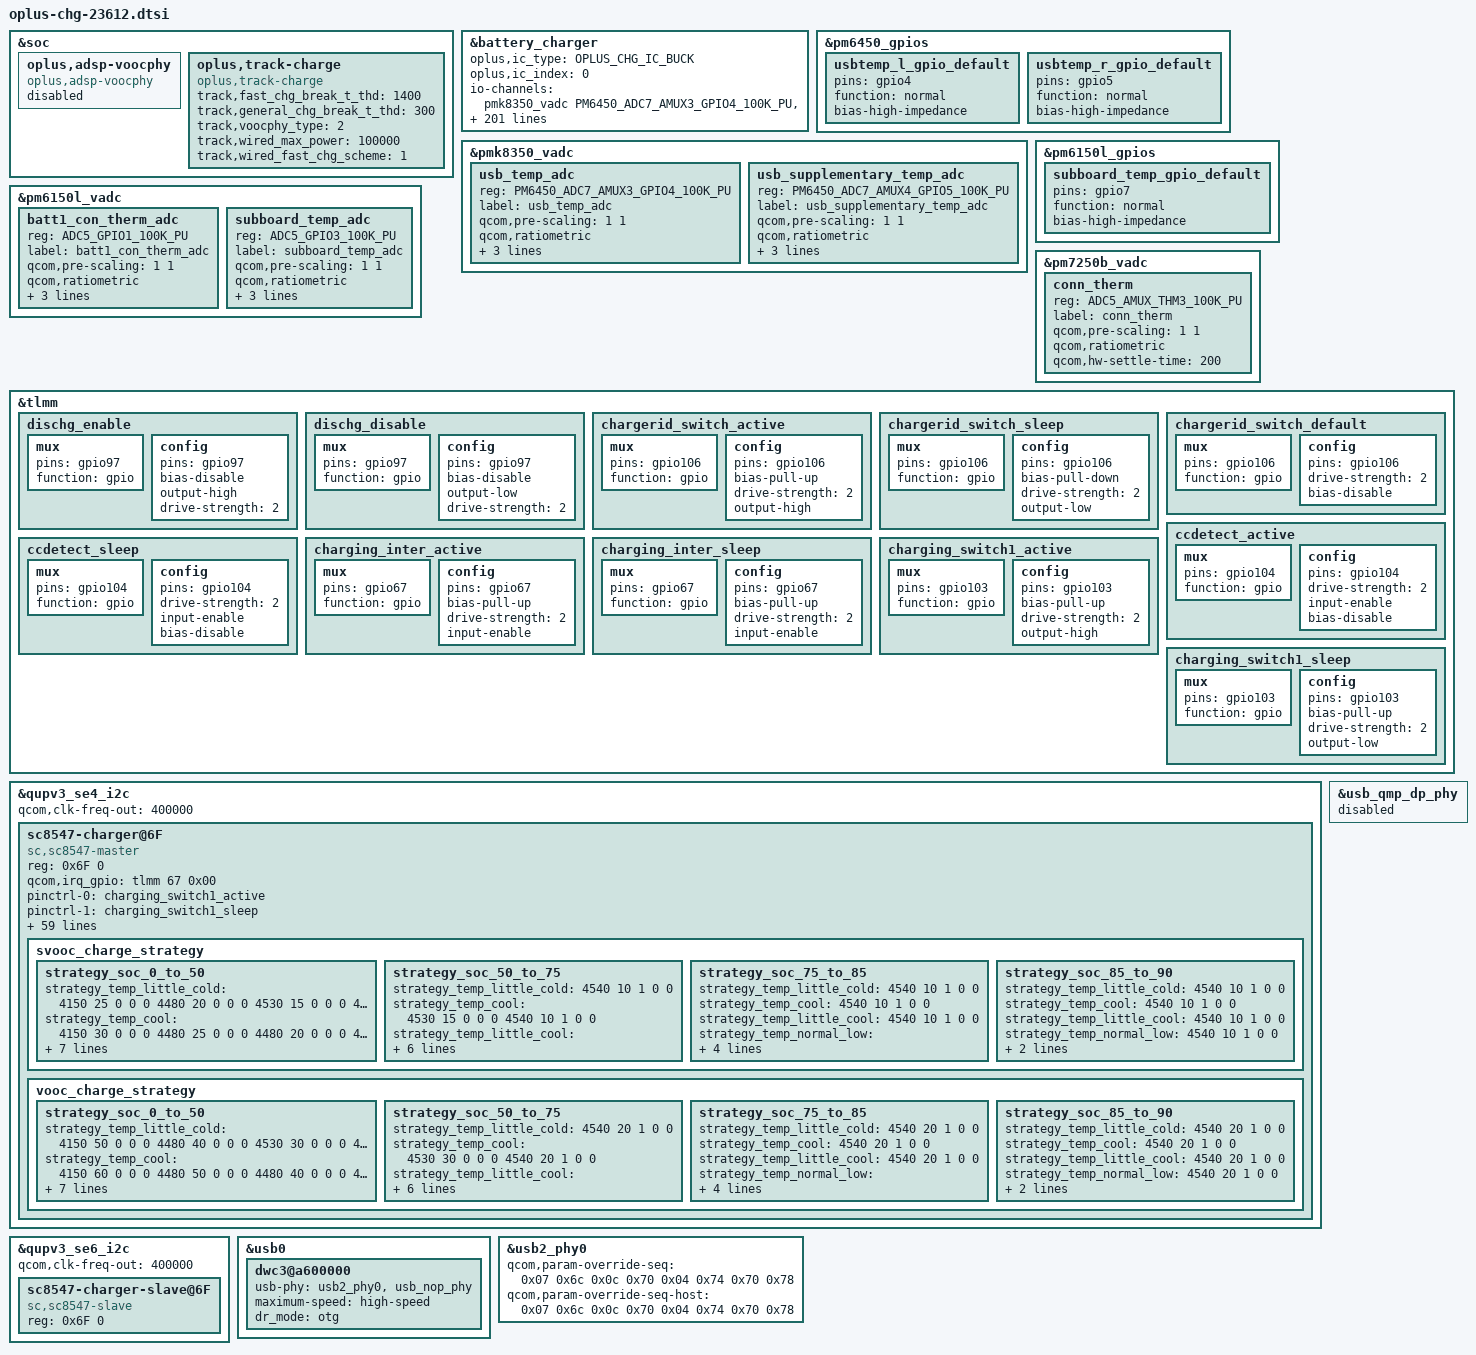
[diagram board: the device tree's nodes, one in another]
#include "oplus_chg_23612.h"

&soc {
	oplus,adsp-voocphy {
		status = "disabled";
		compatible = "oplus,adsp-voocphy";
	};
};
&battery_charger {
	oplus,ic_type = <OPLUS_CHG_IC_BUCK>;
	oplus,ic_index = <0>;
};

&soc {
	oplus,track-charge {
		compatible = "oplus,track-charge";
		track,fast_chg_break_t_thd = <1400>;
		track,general_chg_break_t_thd = <300>;
		track,voocphy_type = <2>;
		track,wired_max_power = <100000>;
		track,wired_fast_chg_scheme = <1>;
	};
};

&pm6450_gpios {
	usbtemp_l_gpio_default: usbtemp_l_gpio_default {
		pins = "gpio4"; /* GPIO 4 */
		function = "normal"; /* normal */
		bias-high-impedance; /* DISABLE GPIO4 for ADC*/
	};
	usbtemp_r_gpio_default: usbtemp_r_gpio_default {
		pins = "gpio5"; /* GPIO 5 */
		function = "normal"; /* normal */
		bias-high-impedance; /* DISABLE GPIO5 for ADC*/
	};
};

&pmk8350_vadc {
	usb_temp_adc {
		reg = <PM6450_ADC7_AMUX3_GPIO4_100K_PU>;
		label = "usb_temp_adc";
		qcom,pre-scaling = <1 1>;
		qcom,ratiometric;
		qcom,hw-settle-time = <200>;
		qcom,scale-fn-type = <OPLUS_ADC_SCALE_HW_CALIB_DEFAULT>;
	};
	usb_supplementary_temp_adc {
		reg = <PM6450_ADC7_AMUX4_GPIO5_100K_PU>;
		label = "usb_supplementary_temp_adc";
		qcom,pre-scaling = <1 1>;
		qcom,ratiometric;
		qcom,hw-settle-time = <200>;
		qcom,scale-fn-type = <OPLUS_ADC_SCALE_HW_CALIB_DEFAULT>;
	};
};

&pm6150l_gpios {
	subboard_temp_gpio_default: subboard_temp_gpio_default {
		pins = "gpio7";
		function = "normal";
		bias-high-impedance;
	};
};

&pm6150l_vadc {
	batt1_con_therm_adc {
		reg = <ADC5_GPIO1_100K_PU>;
		label = "batt1_con_therm_adc";
		qcom,pre-scaling = <1 1>;
		qcom,ratiometric;
		qcom,hw-settle-time = <200>;
		qcom,scale-fn-type = <OPLUS_ADC_SCALE_HW_CALIB_THERM_100K_PULLUP>;
	};
	subboard_temp_adc {
		reg = <ADC5_GPIO3_100K_PU>;
		label = "subboard_temp_adc";
		qcom,pre-scaling = <1 1>;
		qcom,ratiometric;
		qcom,hw-settle-time = <200>;
		qcom,scale-fn-type = <OPLUS_ADC_SCALE_HW_CALIB_THERM_100K_PULLUP>;
	};
};

&pm7250b_vadc {
	conn_therm {
		reg = <ADC5_AMUX_THM3_100K_PU>;
		label = "conn_therm";
		qcom,pre-scaling = <1 1>;
		qcom,ratiometric;
		qcom,hw-settle-time = <200>;
	};
};

&battery_charger {
	io-channels = <&pmk8350_vadc PM6450_ADC7_AMUX3_GPIO4_100K_PU>,
			<&pmk8350_vadc PM6450_ADC7_AMUX4_GPIO5_100K_PU>,
			<&pm6150l_vadc ADC5_GPIO1_100K_PU>,
			<&pm6150l_vadc ADC5_GPIO3_100K_PU>,
			<&pm7250b_vadc ADC5_AMUX_THM3_100K_PU>;

	io-channel-names = "usb_temp_adc",
			"usb_supplementary_temp_adc",
			"batt1_con_therm_adc",
			"subboard_temp_adc",
			"conn_therm";
};

&tlmm 
{
	dischg_enable: dischg_enable {
		mux {
			pins = "gpio97";
			function = "gpio";
		};
		config {
			pins = "gpio97";
			bias-disable; //No Pull
			output-high;
			drive-strength = <2>;
		};
	};

	dischg_disable: dischg_disable {
		mux {
			pins = "gpio97";
			function = "gpio";
		};
		config {
			pins = "gpio97";
			bias-disable; //No Pull
			output-low;
			drive-strength = <2>;
		};
	};

	chargerid_switch_active: chargerid_switch_active {
		mux {
			pins = "gpio106";
			function = "gpio";
		};
		config {
			pins = "gpio106";
			bias-pull-up; /* NO pull */
			drive-strength = <2>; /* 2 MA */
			output-high;
		};
	};

	chargerid_switch_sleep: chargerid_switch_sleep {
		mux {
			pins = "gpio106";
			function = "gpio";
		};
		config {
			pins = "gpio106";
			bias-pull-down; /* NO pull */
			drive-strength = <2>; /* 2 MA */
			output-low;
		};
	};

	chargerid_switch_default: chargerid_switch_default {
		mux {
			pins = "gpio106";
			function = "gpio";
		};
		config {
			pins = "gpio106";
			drive-strength = <2>; /* 2 MA */
			bias-disable;
		};
	};

	ccdetect_active: ccdetect_active {
		mux {
			pins = "gpio104";
			function = "gpio";
		};

		config {
			pins = "gpio104";
			drive-strength = <2>;
			input-enable;
			//bias-pull-up; /*PULL UP*/
			bias-disable;
		};
	};

	ccdetect_sleep: ccdetect_sleep {
		mux {
			pins = "gpio104";
			function = "gpio";
		};

		config {
			pins = "gpio104";
			drive-strength = <2>;
			//output-low;
			//bias-pull-down; /*PULL DOWN*/
			input-enable;
			bias-disable;
		};
	};

	charging_inter_active: charging_inter_active {
		mux {
			pins = "gpio67";
			function = "gpio";
		};
		config {
			pins = "gpio67";
			bias-pull-up; /* NO pull */
			drive-strength = <2>; /* 2 MA */
			input-enable;
		};
	};

	charging_inter_sleep: charging_inter_sleep {
		mux {
			pins = "gpio67";
			function = "gpio";
		};
		config {
			pins = "gpio67";
			bias-pull-up; /* NO pull */
			drive-strength = <2>; /* 2 MA */
			input-enable;
		};
	};
	charging_switch1_active: charging_switch1_active {
		mux {
			pins = "gpio103";
			function = "gpio";
		};
		config {
			pins = "gpio103";
			bias-pull-up; /* NO pull */
			drive-strength = <2>; /* 2 MA */
			output-high;
		};
	};

	charging_switch1_sleep: charging_switch1_sleep {
		mux {
			pins = "gpio103";
			function = "gpio";
		};
		config {
			pins = "gpio103";
			bias-pull-up; /* NO pull */
			drive-strength = <2>; /* 2 MA */
			output-low;
		};
	};
};

&battery_charger {
	//for oplus chg framework:
	oplus,chg_ops = "plat-pmic";
	qcom,smart_charging_screenoff;
	//qcom,smart_chg_bcc_support;
	qcom,input_current_charger_ma = <2000>;
	qcom,pd_input_current_charger_ma = <2000>;
	qcom,qc_input_current_charger_ma = <2000>;
	qcom,input_current_usb_ma = <500>;
	qcom,input_current_cdp_ma = <1500>;
	qcom,input_current_led_ma = <1200>;
	qcom,input_current_led_ma_high = <1200>;
	qcom,input_current_led_ma_warm = <1500>;
	qcom,input_current_led_ma_normal = <2000>;
	qcom,led_warm_bat_decidegc = <350>;
	qcom,led_high_bat_decidegc = <370>;
	qcom,input_current_camera_ma = <1200>;
	qcom,input_current_vooc_led_ma_high = <1800>;
	qcom,input_current_vooc_led_ma_warm = <1800>;
	qcom,input_current_vooc_led_ma_normal = <3600>;
	qcom,input_current_vooc_ma_normal = <3600>;
	qcom,vooc_temp_bat_normal_decidegc = <350>;
	qcom,input_current_vooc_ma_warm = <3200>;
	qcom,vooc_temp_bat_warm_decidegc = <370>;
	qcom,input_current_vooc_ma_high = <2200>;
	qcom,vooc_temp_bat_hot_decidegc = <440>;
	qcom,charger_current_vooc_ma_normal = <1800>;

	qcom,chg_ctrl_by_calling;
	qcom,input_current_calling_ma = <1500>;

	//qcom,input_current_led_ma_overtemp = <900>;
	qcom,overtemp_bat_decidegc = <350>;
	qcom,iterm_disabled = <0>;
	qcom,iterm_ma = <260>;
	qcom,recharge-mv = <100>;
	qcom,batt_capacity_mah = <5000>;/*typical capacity*/
	//qcom,batt_capacity_mah = <4390>; /*rated capacity*/

	qcom,removed_bat_decidegc = <390>;  /*<-19C*/

	qcom,cold_bat_decidegc = <100>;  /*-10C~0C*/
	qcom,temp_cold_vfloat_mv = <4470>;
	qcom,temp_cold_fastchg_current_ma = <1250>;

	qcom,little_cold_bat_decidegc = <0>;	/*0C~5C*/
	qcom,temp_little_cold_vfloat_mv = <4470>;
	qcom,temp_little_cold_fastchg_current_ma_high = <2200>;
	qcom,temp_little_cold_fastchg_current_ma_low = <2200>;
	qcom,temp_little_cold_fastchg_current_ma = <2200>;
	qcom,pd_temp_little_cold_fastchg_current_ma_high = <3300>;
	qcom,pd_temp_little_cold_fastchg_current_ma_low = <3300>;
	qcom,qc_temp_little_cold_fastchg_current_ma_high = <3300>;
	qcom,qc_temp_little_cold_fastchg_current_ma_low = <3300>;

	qcom,cool_bat_decidegc = <50>;	/*5C~12C*/
	qcom,temp_cool_vfloat_mv = <4470>;
	qcom,temp_cool_fastchg_current_ma_high = <2200>;
	qcom,temp_cool_fastchg_current_ma_low = <2200>;
	qcom,pd_temp_cool_fastchg_current_ma_high = <3600>;
	qcom,pd_temp_cool_fastchg_current_ma_low = <3600>;
	qcom,qc_temp_cool_fastchg_current_ma_high = <3600>;
	qcom,qc_temp_cool_fastchg_current_ma_low = <3600>;

	qcom,little_cool_bat_decidegc = <120>;	/*12C~16C*/
	qcom,temp_little_cool_vfloat_mv = <4470>;
	qcom,temp_little_cool_fastchg_current_ma = <2200>;
	qcom,pd_temp_little_cool_fastchg_current_ma = <3600>;
	qcom,qc_temp_little_cool_fastchg_current_ma = <3600>;

	qcom,normal_bat_decidegc = <160>;	/*16C~44C*/
	qcom,temp_normal_fastchg_current_ma = <2200>;
	qcom,temp_normal_vfloat_mv = <4470>;
	qcom,pd_temp_normal_fastchg_current_ma = <3600>;
	qcom,qc_temp_normal_fastchg_current_ma = <3600>;

	qcom,warm_bat_decidegc = <450>;		/*45C~53C*/ /*8pin Bat Vooc project need add 3 degree C*/
	qcom,temp_warm_vfloat_mv = <4130>;
	qcom,temp_warm_fastchg_current_ma = <2200>;
	qcom,pd_temp_warm_fastchg_current_ma = <2750>;
	qcom,qc_temp_warm_fastchg_current_ma = <2750>;
	qcom,temp_warm_fastchg_current_ma_led_on = <1000>;

	qcom,hot_bat_decidegc = <530>;

	qcom,non_standard_vfloat_mv = <3980>;
	qcom,non_standard_fastchg_current_ma = <500>;

	qcom,short_c_bat_cv_mv = <4330>;
	qcom,short_c_bat_vfloat_mv = <3800>;
	qcom,short_c_bat_fastchg_current_ma = <512>;

	qcom,cold_vfloat_sw_limit = <4420>;
	qcom,little_cold_vfloat_sw_limit = <4420>;
	qcom,cool_vfloat_sw_limit = <4420>;
	qcom,little_cool_vfloat_sw_limit = <4420>;
	qcom,normal_vfloat_sw_limit = <4420>;
	qcom,warm_vfloat_sw_limit = <4080>;
	qcom,non_standard_vfloat_sw_limit = <3930>;
	qcom,short_c_bat_vfloat_sw_limit = <3750>;

	qcom,max_chg_time_sec = <63864>;
	qcom,charger_hv_thr = <9900>;
	qcom,charger_recv_thr = <9500>;
	qcom,charger_lv_thr = <3400>;
	qcom,vbatt_full_thr = <4470>;
	qcom,vbatt_hv_thr = <4600>;
	qcom,vfloat_step_mv = <8>;
	qcom,non_standard_vfloat_over_sw_limit = <3990>;
	qcom,cold_vfloat_over_sw_limit = <4480>;
	qcom,little_cold_vfloat_over_sw_limit = <4480>;
	qcom,cool_vfloat_over_sw_limit = <4480>;
	qcom,little_cool_vfloat_over_sw_limit = <4480>;
	qcom,normal_vfloat_over_sw_limit = <4480>;
	qcom,warm_vfloat_over_sw_limit = <4140>;


	qcom,support_usbtemp_protect_v2;
	qcom,usbtemp_batt_temp_low = <50>;
	qcom,usbtemp_batt_temp_high = <50>;
	qcom,usbtemp_ntc_temp_low = <57>;
	qcom,usbtemp_ntc_temp_high = <69>;
	qcom,usbtemp_temp_gap_low_with_batt_temp = <7>;
	qcom,usbtemp_temp_gap_high_with_batt_temp = <12>;
	qcom,usbtemp_temp_gap_low_without_batt_temp = <12>;
	qcom,usbtemp_temp_gap_high_without_batt_temp = <24>;
	qcom.usbtemp_rise_fast_temp_low = <3>;
	qcom.usbtemp_rise_fast_temp_high = <3>;
	qcom.usbtemp_rise_fast_temp_count_low = <30>;
	qcom.usbtemp_rise_fast_temp_count_high = <20>;

	qcom,usbtemp_cool_down_ntc_low = <54>;
	qcom,usbtemp_cool_down_ntc_high = <65>;
	qcom,usbtemp_cool_down_gap_low = <12>;
	qcom,usbtemp_cool_down_gap_high = <20>;
	qcom,usbtemp_cool_down_recover_ntc_low = <48>;
	qcom,usbtemp_cool_down_recover_ntc_high = <60>;
	qcom,usbtemp_cool_down_recover_gap_low = <6>;
	qcom,usbtemp_cool_down_recover_gap_high = <15>;

	qcom,vbatt_power_off = <3300>;
	qcom,vbatt_soc_1 = <3410>;
	qcom,vooc_project = <13>;//11v6.1A
	//qcom,vbatt_num = <2>;
	qcom,ffc_support;
	qcom,dual_ffc;
	//recharge_after_full;
	//qcom,wireless_support;
	//qcom,wpc_no_chargerpump;

	qcom,normal_vterm_hw_inc = <18>;
	qcom,non_normal_vterm_hw_inc = <18>;

	qcom,ff1_normal_fastchg_ma = <1550>;
	qcom,ff1_warm_fastchg_ma = <1550>;
	qcom,ffc2_normal_fastchg_ma = <1500>;/*12C~35c*/
	qcom,ffc2_temp_warm_decidegc = <350>;
	qcom,ffc2_warm_fastchg_ma = <1550>;/*35C~40c*/
	qcom,ffc2_temp_high_decidegc = <430>;
	qcom,ffc2_temp_low_decidegc = <160>;
	qcom,ffc2_exit_step_ma = <150>;
	qcom,ff1_exit_step_ma = <150>;
	qcom,ff1_warm_exit_step_ma = <150>;

	qcom,ffc_normal_vfloat_sw_limit = <4500>;
	qcom,ffc2_normal_vfloat_sw_limit = <4500>;
	qcom,ffc2_warm_vfloat_sw_limit = <4500>;
	qcom,ffc_temp_normal_vfloat_mv = <4600>;
	qcom,ffc1_temp_normal_vfloat_mv = <4600>;
	qcom,ffc2_temp_normal_vfloat_mv = <4600>;
	qcom,ffc_normal_vfloat_over_sw_limit = <4600>;
	qcom,ffc1_normal_vfloat_over_sw_limit = <4600>;
	qcom,ffc2_normal_vfloat_over_sw_limit = <4600>;

	qcom,default_iterm_ma = <260>;
	qcom,default_temp_normal_fastchg_current_ma = <2200>;
	qcom,default_normal_vfloat_sw_limit = <4420>;
	qcom,default_temp_normal_vfloat_mv = <4470>;
	qcom,default_normal_vfloat_over_sw_limit = <4480>;

	qcom,default_temp_little_cool_fastchg_current_ma = <2200>;
	qcom,default_little_cool_vfloat_sw_limit = <4420>;
	qcom,default_temp_little_cool_vfloat_mv = <4470>;
	qcom,default_little_cool_vfloat_over_sw_limit = <4480>;
	qcom,vooc-max-input-volt-support = <10000>;     //10V
	qcom,vooc-max-input-current-support = <6500>;   //6.5A

	oplus,boot_reset_adapter;
	///qcom,offset_temp = <30>;
	//for control:
	//qcom,suspend_after_full;
	qcom,support_abnormal_adapter;
	qcom,check_batt_full_by_sw;
	qcom,support_subboard_ntc;
	//qcom,external_gauge;
	qcom,chg_ctrl_by_lcd;
	//qcom,chg_ctrl_by_vooc;
	qcom,chg_ctrl_by_camera;
	qcom,sw_vfloat_over_protect_enable;
	qcom,usbtemp_batttemp_gap = <10>;
	qcom,voocphy_support = <3>;
	qcom,fg_info_package_read_support;
	qcom,pmic-is-pm7250b;
	qcom,chargerid_switch-gpio = <&tlmm 106 0x00>;
	//for PD9V or QC9V
	//qcom,vbatt_pdqc_to_5v_thr = <4100>;
	qcom,vbatt_pdqc_to_9v_thr = <5000>;/*always 9v*/
	qcom,vooc_show_ui_soc_decimal;
	qcom,ui_soc_decimal_speedmin = <20>;//2A
	qcom,otg_scheme = <1>;//0:cid 1:ccdetect_gpio 2:switch
	qcom,ccdetect-gpio = <&tlmm 104 0x00>;
	qcom,dischg-gpio = <&tlmm 97 0x00>;
	pinctrl-names = "dischg_enable", "dischg_disable",
		"chargerid_switch_active", "chargerid_switch_sleep", "chargerid_switch_default",
		"ccdetect_active", "ccdetect_sleep",
		"usbtemp_l_gpio_default", "usbtemp_r_gpio_default",
		"subboard_temp_gpio_default";

	pinctrl-0 = <&dischg_enable>;
	pinctrl-1 = <&dischg_disable>;
	pinctrl-2 = <&chargerid_switch_active>;
	pinctrl-3 = <&chargerid_switch_sleep>;
	pinctrl-4 = <&chargerid_switch_default>;
	pinctrl-5 = <&ccdetect_active>;
	pinctrl-6 = <&ccdetect_sleep>;
	pinctrl-7 = <&usbtemp_l_gpio_default>;
	pinctrl-8 = <&usbtemp_r_gpio_default>;
	pinctrl-9 = <&subboard_temp_gpio_default>;
};

&qupv3_se4_i2c {
	status = "ok";//status = "ok";
	qcom,clk-freq-out = <400000>;
	sc8547-charger@6F{
		status = "okay";
		compatible = "sc,sc8547-master";
		reg = <0x6F 0>;

		qcom,irq_gpio = <&tlmm 67 0x00>;
		pinctrl-names = "switch1_act_switch2_act", "switch1_sleep_switch2_sleep",
			"charging_inter_active", "charging_inter_sleep"; 
                        //, "slave_charging_inter_default";
		pinctrl-0 = <&charging_switch1_active>;
		pinctrl-1 = <&charging_switch1_sleep>;
		pinctrl-2 = <&charging_inter_active>;
		pinctrl-3 = <&charging_inter_sleep>;
		//pinctrl-4 = <&slave_charging_inter_default>;
		qcom,charging_switch1-gpio = <&tlmm 103 0x00>;

		qcom,voocphy_dual_cp_support;
		qcom,copycat_vooc_support;
		//qcom,external_gauge_support;
		qcom,slave_cp_enable_thr = <1400>;		//2000-100mA
		qcom,slave_cp_disable_thr_high = <1100>;	//1500+100mA
		qcom,voocphy_current_default = <61>;

		qcom,svooc_cool_down_current_limit = <122 20 20 24 30 34 40 44 50 54 60 64 70 74 80 90 100 110 122>;
		qcom,vooc_cool_down_current_limit = <61 20 20 24 30 34 40 44 50 54 61>;
		qcom,abnormal_adapter_current = <122 100 80 60 40>;
		qcom,vooc_little_cold_full_voltage = <4540>;
		qcom,vooc_cool_full_voltage = <4540>;
		qcom,vooc_warm_full_voltage = <4130>;
		qcom,vooc_1time_full_voltage = <4550>;
		qcom,vooc_ntime_full_voltage = <4540>;
		qcom,low_curr_full_t1 = <160>;
		qcom,low_curr_full_t2 = <350>;
		qcom,low_curr_full_t3 = <430>;
		qcom,range1_low_curr_full = <1350 4540
			1250 4535
			1150 4520
			1050 4510
			950 4500>;
		qcom,range2_low_curr_full = <1400 4540
			1300 4535
			1200 4520
			1100 4510
			1000 4500>;

		qcom,vooc_multistep_initial_batt_temp = <1000>;
		qcom,vooc_little_cool_temp = <160>;
		qcom,vooc_cool_temp = <120>;
		qcom,vooc_little_cold_temp = <50>;
		qcom,vooc_normal_low_temp = <350>;
		qcom,vooc_strategy_normal_current = <122>;
		qcom,vooc_normal_to_little_cool_current = <100>;
		qcom,vooc_batt_over_high_temp = <510>;
		qcom,vooc-low-temp = <0>;
		qcom,vooc-high-temp = <500>;
		qcom,vooc-low-soc = <0>;
		qcom,vooc-high-soc = <90>;
		qcom,vooc-normal-high-temp = <430>;
		qcom,vooc-warm-allow-vol = <4000>;
		qcom,vooc-warm-allow-soc = <50>;

		qcom,vooc_strategy1_batt_high_temp0 = <385>;
		qcom,vooc_strategy1_batt_high_temp1 = <395>;
		qcom,vooc_strategy1_batt_high_temp2 = <420>;
		qcom,vooc_strategy1_batt_low_temp2 = <410>;
		qcom,vooc_strategy1_batt_low_temp1 = <385>;
		qcom,vooc_strategy1_batt_low_temp0 = <375>;

		qcom,vooc_strategy1_high_current0 = <80>;
		qcom,vooc_strategy1_high_current1 = <60>;
		qcom,vooc_strategy1_high_current2 = <40>;
		qcom,vooc_strategy1_low_current2 = <60>;
		qcom,vooc_strategy1_low_current1 = <80>;
		qcom,vooc_strategy1_low_current0 = <122>;

		qcom,voocphy_ibat_over_current = <13500>;
		qcom,voocphy_cp_max_ibus = <3500>;

		svooc_batt_sys_curve = <0 1 0 1 0 0 0	// 4000mA
			1 1 1 1 0 0 0	// 4604mV
			0 0 1 1 0 1 0	// 2600mA
			1 1 1 1 0 0 0	// 4604mV
			0 0 0 1 0 1 1	// 1100mA
			1 1 1 1 0 0 0>;	// 4604mV

		vooc_batt_sys_curve =  <0 1 0 1 0 0 0	// 4000mA
			1 1 1 1 0 0 0	// 4604mV
			0 0 1 1 0 1 0	// 2600mA
			1 1 1 1 0 0 0	// 4604mV
			0 0 0 1 0 1 1	// 1100mA
			1 1 1 1 0 0 0>;	// 4604mV

		svooc_charge_strategy {
			strategy_soc_0_to_50 {
				strategy_temp_little_cold =	<4150 25 0 0 0
					4480 20 0 0 0
					4530 15 0 0 0
					4540 10 1 0 0>;
				strategy_temp_cool =		<4150 30 0 0 0
					4480 25 0 0 0
					4480 20 0 0 0
					4530 15 0 0 0
					4540 10 1 0 0>;
				strategy_temp_little_cool =	<4150 50 0 0 0
					4480 40 0 0 0
					4530 30 0 0 0
					4530 25 0 0 0
					4530 20 0 0 0
					4530 15 0 0 0
					4540 10 1 0 0>;
				strategy_temp_normal_low =	<4200 61 0 0 0 //min*60*1000/500
					4230 50 0 0 0 //min*60*1000/500
					4480 40 0 0 0 //min*60*1000/500
					4530 30 0 0 0
					4530 25 0 0 0
					4530 20 0 0 0
					4530 15 0 0 0
					4540 10 1 0 0>;
				strategy_temp_normal_high =	<4200 61 0 0 0 //min*60*1000/500
					4230 50 0 0 0 //min*60*1000/500
					4480 40 0 0 0 //min*60*1000/500
					4530 30 0 0 0
					4530 25 0 0 0
					4530 20 0 0 0
					4530 15 0 0 0
					4540 10 1 0 0>;
				strategy_temp_warm =		<4130 10 1 0 0>;
			};

			strategy_soc_50_to_75 {
				strategy_temp_little_cold =	<4540 10 1 0 0>;
				strategy_temp_cool =		<4530 15 0 0 0
					4540 10 1 0 0>;
				strategy_temp_little_cool =	<4530 20 0 0 0
					4530 15 0 0 0
					4540 10 1 0 0>;
				strategy_temp_normal_low =	<4530 25 0 0 0
					4530 20 0 0 0
					4530 15 0 0 0
					4540 10 1 0 0>;
				strategy_temp_normal_high =	<4530 25 0 0 0
					4530 20 0 0 0
					4530 15 0 0 0
					4540 10 1 0 0>;
				strategy_temp_warm =		<4130 10 1 0 0>;
			};

			strategy_soc_75_to_85 {
				strategy_temp_little_cold =	<4540 10 1 0 0>;
				strategy_temp_cool =		<4540 10 1 0 0>;
				strategy_temp_little_cool =	<4540 10 1 0 0>;
				strategy_temp_normal_low =	<4530 15 0 0 0
					4540 10 1 0 0>;
				strategy_temp_normal_high =	<4530 15 0 0 0
					4540 10 1 0 0>;
				strategy_temp_warm =		<4130 10 1 0 0>;
			};

			strategy_soc_85_to_90 {
				strategy_temp_little_cold =	<4540 10 1 0 0>;
				strategy_temp_cool =		<4540 10 1 0 0>;
				strategy_temp_little_cool =	<4540 10 1 0 0>;
				strategy_temp_normal_low =	<4540 10 1 0 0>;
				strategy_temp_normal_high =	<4540 10 1 0 0>;
				strategy_temp_warm =		<4130 10 1 0 0>;
			};
		};

		vooc_charge_strategy {
			strategy_soc_0_to_50 {
				strategy_temp_little_cold =	<4150 50 0 0 0
					4480 40 0 0 0
					4530 30 0 0 0
					4540 20 1 0 0>;
				strategy_temp_cool =		<4150 60 0 0 0
					4480 50 0 0 0
					4480 40 0 0 0
					4530 30 0 0 0
					4540 20 1 0 0>;
				strategy_temp_little_cool =	<4530 60 0 0 0
					4530 50 0 0 0
					4530 40 0 0 0
					4530 30 0 0 0
					4540 20 1 0 0>;
				strategy_temp_normal_low =	<4530 60 0 0 0
					4530 50 0 0 0
					4530 40 0 0 0
					4530 30 0 0 0
					4540 20 1 0 0>;
				strategy_temp_normal_high =	<4530 60 0 0 0
					4530 50 0 0 0
					4530 40 0 0 0
					4530 30 0 0 0
					4540 20 1 0 0>;
				strategy_temp_warm =		<4130 20 1 0 0>;
			};

			strategy_soc_50_to_75 {
				strategy_temp_little_cold =	<4540 20 1 0 0>;
				strategy_temp_cool =		<4530 30 0 0 0
					4540 20 1 0 0>;
				strategy_temp_little_cool =	<4530 40 0 0 0
					4530 30 0 0 0
					4540 20 1 0 0>;
				strategy_temp_normal_low =	<4530 50 0 0 0
					4530 40 0 0 0
					4530 30 0 0 0
					4540 20 1 0 0>;
				strategy_temp_normal_high =	<4530 50 0 0 0
					4530 40 0 0 0
					4530 30 0 0 0
					4540 20 1 0 0>;
				strategy_temp_warm =		<4130 20 1 0 0>;
			};

			strategy_soc_75_to_85 {
				strategy_temp_little_cold =	<4540 20 1 0 0>;
				strategy_temp_cool =		<4540 20 1 0 0>;
				strategy_temp_little_cool =	<4540 20 1 0 0>;
				strategy_temp_normal_low =	<4530 30 0 0 0
					4540 20 1 0 0>;
				strategy_temp_normal_high =	<4530 30 0 0 0
					4540 20 1 0 0>;
				strategy_temp_warm =		<4130 20 1 0 0>;
			};

			strategy_soc_85_to_90 {
				strategy_temp_little_cold =	<4540 20 1 0 0>;
				strategy_temp_cool =		<4540 20 1 0 0>;
				strategy_temp_little_cool =	<4540 20 1 0 0>;
				strategy_temp_normal_low =	<4540 20 1 0 0>;
				strategy_temp_normal_high =	<4540 20 1 0 0>;
				strategy_temp_warm =		<4130 20 1 0 0>;
			};
		};
	};
};

&qupv3_se6_i2c {
	status = "ok";
	qcom,clk-freq-out = <400000>;
	sc8547-charger-slave@6F{
		status = "okay";
		compatible = "sc,sc8547-slave";
		reg = <0x6F 0>;
	};
};

&usb_qmp_dp_phy {
	status = "disabled";
};


&usb0 {
	/delete-property/ extcon;
	dwc3@a600000 {
		usb-phy = <&usb2_phy0>, <&usb_nop_phy>;
		maximum-speed = "high-speed";
		dr_mode = "otg";
	};
};


&usb2_phy0 {
	qcom,param-override-seq =
		<0x07 0x6c
		0x0c 0x70
		0x04 0x74
		0x70 0x78>;

	qcom,param-override-seq-host =
		<0x07 0x6c
		0x0c 0x70
		0x04 0x74
		0x70 0x78>;
};

